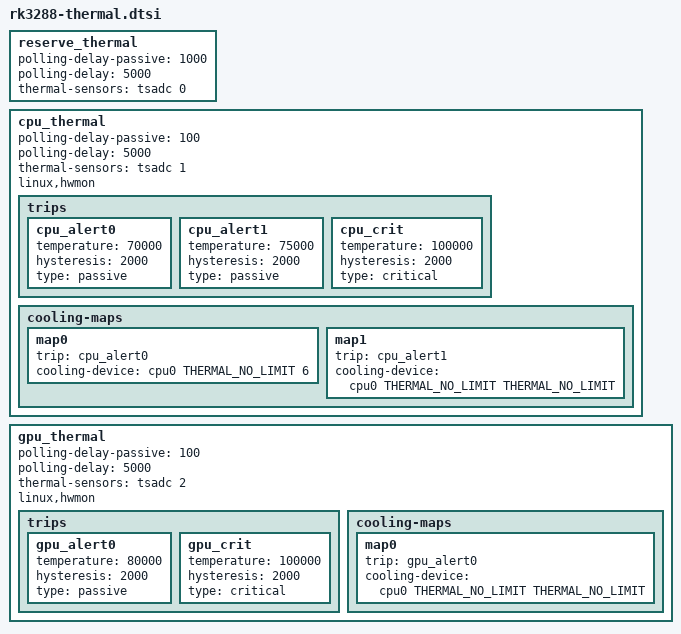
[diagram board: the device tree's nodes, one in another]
// SPDX-License-Identifier: GPL-2.0
/*
 * Device Tree Source for RK3288 SoC thermal
 *
 * Copyright (c) 2014, Fuzhou Rockchip Electronics Co., Ltd
 */

#include <dt-bindings/thermal/thermal.h>

reserve_thermal: reserve_thermal {
	polling-delay-passive = <1000>; /* milliseconds */
	polling-delay = <5000>; /* milliseconds */

			/* sensor	ID */
	thermal-sensors = <&tsadc	0>;

};

cpu_thermal: cpu_thermal {
	polling-delay-passive = <100>; /* milliseconds */
	polling-delay = <5000>; /* milliseconds */

			/* sensor	ID */
	thermal-sensors = <&tsadc	1>;
	linux,hwmon;

	trips {
		cpu_alert0: cpu_alert0 {
			temperature = <70000>; /* millicelsius */
			hysteresis = <2000>; /* millicelsius */
			type = "passive";
		};
		cpu_alert1: cpu_alert1 {
			temperature = <75000>; /* millicelsius */
			hysteresis = <2000>; /* millicelsius */
			type = "passive";
		};
		cpu_crit: cpu_crit {
			temperature = <100000>; /* millicelsius */
			hysteresis = <2000>; /* millicelsius */
			type = "critical";
		};
	};

	cooling-maps {
		map0 {
			trip = <&cpu_alert0>;
			cooling-device =
				<&cpu0 THERMAL_NO_LIMIT 6>;
		};
		map1 {
			trip = <&cpu_alert1>;
			cooling-device =
				<&cpu0 THERMAL_NO_LIMIT THERMAL_NO_LIMIT>;
		};
	};
};

gpu_thermal: gpu_thermal {
	polling-delay-passive = <100>; /* milliseconds */
	polling-delay = <5000>; /* milliseconds */

			/* sensor	ID */
	thermal-sensors = <&tsadc	2>;
	linux,hwmon;

	trips {
		gpu_alert0: gpu_alert0 {
			temperature = <80000>; /* millicelsius */
			hysteresis = <2000>; /* millicelsius */
			type = "passive";
		};
		gpu_crit: gpu_crit {
			temperature = <100000>; /* millicelsius */
			hysteresis = <2000>; /* millicelsius */
			type = "critical";
		};
	};

	cooling-maps {
		map0 {
			trip = <&gpu_alert0>;
			cooling-device =
				<&cpu0 THERMAL_NO_LIMIT THERMAL_NO_LIMIT>;
		};
	};
};
